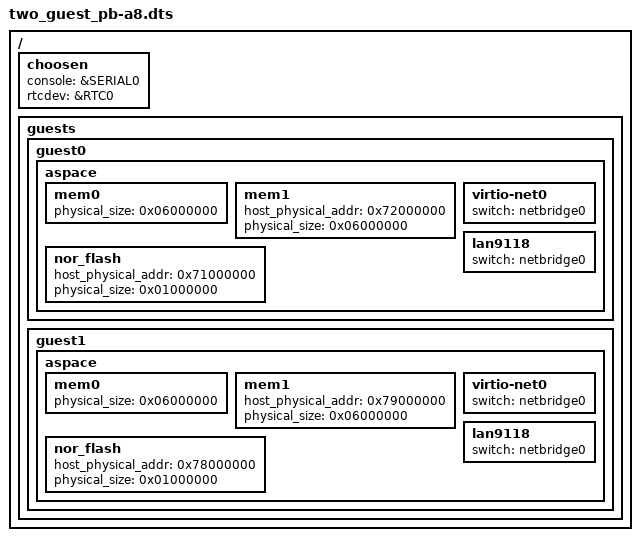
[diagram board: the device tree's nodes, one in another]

/dts-v1/;

/include/ "pb-a8.dtsi"

/include/ "../../common/guests/two_guest_pb-a8.dtsi"

/ {
	choosen {
		console = &SERIAL0;
		rtcdev = &RTC0;
	};

	guests {
		guest0 {
			aspace {
				mem0 {
					physical_size = <0x06000000>; /* 96 MB */
				};

				mem1 {
					host_physical_addr = <0x72000000>;
					physical_size = <0x06000000>; /* 96 MB */
				};

				virtio-net0 {
					switch = "netbridge0";
				};

				nor_flash {
					host_physical_addr = <0x71000000>;
					physical_size = <0x01000000>; /* 16 MB */
				};

				lan9118 {
					switch = "netbridge0";
				};
			};
		};

		guest1 {
			aspace {
				mem0 {
					physical_size = <0x06000000>; /* 96 MB */
				};

				mem1 {
					host_physical_addr = <0x79000000>;
					physical_size = <0x06000000>; /* 96 MB */
				};

				virtio-net0 {
					switch = "netbridge0";
				};

				nor_flash {
					host_physical_addr = <0x78000000>;
					physical_size = <0x01000000>; /* 16 MB */
				};

				lan9118 {
					switch = "netbridge0";
				};
			};
		};
	};
};
